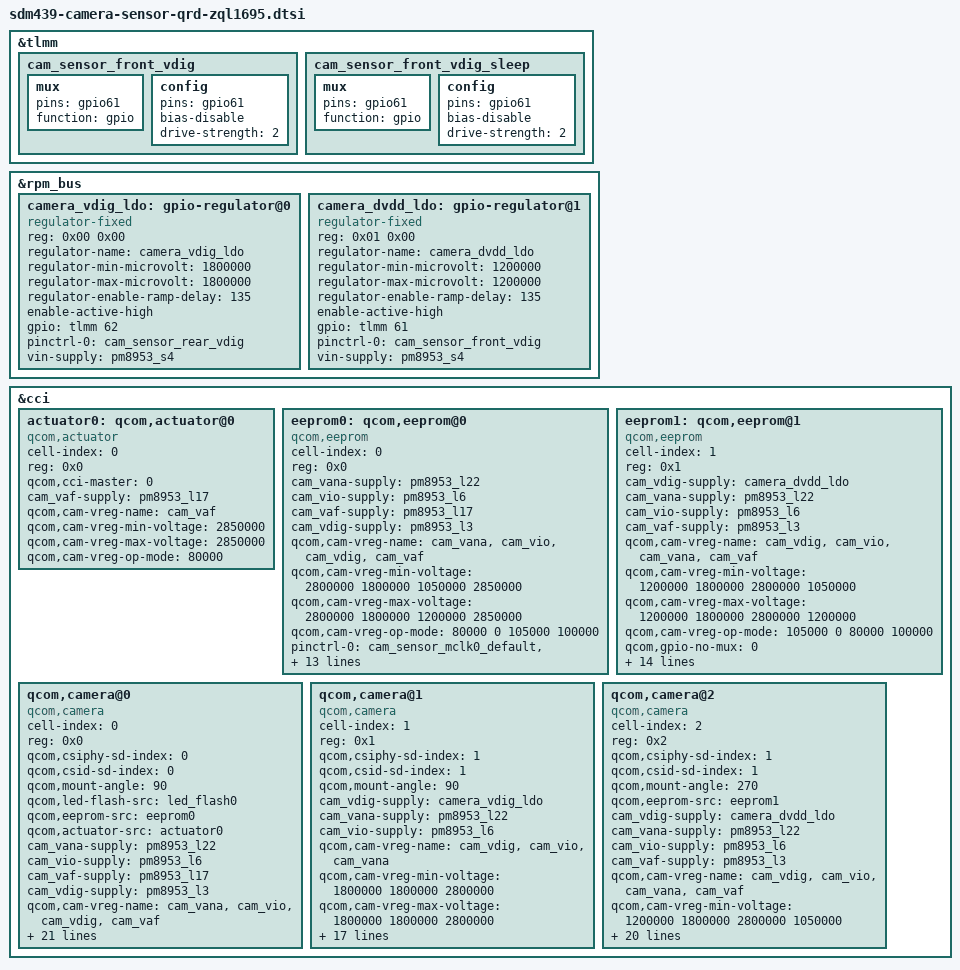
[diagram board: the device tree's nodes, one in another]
/*
 * Copyright (c) 2015-2016, 2018-2019 The Linux Foundation. All rights reserved.
 *
 * This program is free software; you can redistribute it and/or modify
 * it under the terms of the GNU General Public License version 2 and
 * only version 2 as published by the Free Software Foundation.
 *
 * This program is distributed in the hope that it will be useful,
 * but WITHOUT ANY WARRANTY; without even the implied warranty of
 * MERCHANTABILITY or FITNESS FOR A PARTICULAR PURPOSE.  See the
 * GNU General Public License for more details.
 */

#include <dt-bindings/clock/msm-clocks-8952.h>

&tlmm{
		cam_sensor_front_vdig: cam_sensor_front_vdig {
			/* VDIG */
			mux {
				pins = "gpio61";
				function = "gpio";
			};

			config {
				pins = "gpio61";
				bias-disable; /* No PULL */
				drive-strength = <2>; /* 2 MA */
			};
		};

		cam_sensor_front_vdig_sleep: cam_sensor_front_vdig_sleep {
			/* VDIG */
			mux {
				pins = "gpio61";
				function = "gpio";
			};

			config {
				pins = "gpio61";
				bias-disable; /* No PULL */
				drive-strength = <2>; /* 2 MA */
			};
		};
};

&rpm_bus {
	camera_vdig_ldo: gpio-regulator@0 {
		compatible = "regulator-fixed";
		reg = <0x00 0x00>;
		regulator-name = "camera_vdig_ldo";
		regulator-min-microvolt = <1800000>;
		regulator-max-microvolt = <1800000>;
		regulator-enable-ramp-delay = <135>;
		enable-active-high;
		gpio = <&tlmm 62 0>;
		pinctrl-names = "default";
		pinctrl-0 = <&cam_sensor_rear_vdig>;
		vin-supply = <&pm8953_s4>;
	};
	camera_dvdd_ldo: gpio-regulator@1 {
		compatible = "regulator-fixed";
		reg = <0x01 0x00>;
		regulator-name = "camera_dvdd_ldo";
		regulator-min-microvolt = <1200000>;
		regulator-max-microvolt = <1200000>;
		regulator-enable-ramp-delay = <135>;
		enable-active-high;
		gpio = <&tlmm 61 0>;
		pinctrl-names = "default";
		pinctrl-0 = <&cam_sensor_front_vdig>;
		vin-supply = <&pm8953_s4>;
	};
};

&cci {
	#address-cells = <1>;
	#size-cells = <0>;

	actuator0: qcom,actuator@0 {
		cell-index = <0>;
		reg = <0x0>;
		compatible = "qcom,actuator";
		qcom,cci-master = <0>;
		cam_vaf-supply = <&pm8953_l17>;
		qcom,cam-vreg-name = "cam_vaf";
		qcom,cam-vreg-min-voltage = <2850000>;
		qcom,cam-vreg-max-voltage = <2850000>;
		qcom,cam-vreg-op-mode = <80000>;
	};

	eeprom0: qcom,eeprom@0 {
		cell-index = <0>;
		compatible = "qcom,eeprom";
		reg = <0x0>;
		cam_vana-supply = <&pm8953_l22>;
		cam_vio-supply = <&pm8953_l6>;
		cam_vaf-supply = <&pm8953_l17>;
		cam_vdig-supply = <&pm8953_l3>;
		qcom,cam-vreg-name = "cam_vana", "cam_vio",
				"cam_vdig", "cam_vaf";
		qcom,cam-vreg-min-voltage = <2800000 1800000 1050000 2850000>;
		qcom,cam-vreg-max-voltage = <2800000 1800000 1200000 2850000>;
		qcom,cam-vreg-op-mode = <80000 0 105000 100000>;
		pinctrl-names = "cam_default", "cam_suspend";
		pinctrl-0 = <&cam_sensor_mclk0_default
				&cam_sensor_rear_reset>;
		pinctrl-1 = <&cam_sensor_mclk0_sleep
				&cam_sensor_rear_reset_sleep>;
		gpios = <&tlmm 26 0>,
			<&tlmm 36 0>;
		qcom,gpio-reset = <1>;
		qcom,gpio-req-tbl-num = <0 1>;
		qcom,gpio-req-tbl-flags = <1 0>;
		qcom,gpio-req-tbl-label = "CAMIF_MCLK0",
			"CAM_RESET0";
		qcom,cci-master = <0>;
		status = "ok";
		clocks = <&clock_gcc clk_mclk0_clk_src>,
				<&clock_gcc clk_gcc_camss_mclk0_clk>;
		clock-names = "cam_src_clk", "cam_clk";
		qcom,clock-rates = <24000000 0>;
	};

    eeprom1: qcom,eeprom@1 {
		cell-index = <1>;
		compatible = "qcom,eeprom";
		reg = <0x1>;
		cam_vdig-supply = <&camera_dvdd_ldo>;
		cam_vana-supply = <&pm8953_l22>;
		cam_vio-supply = <&pm8953_l6>;
		cam_vaf-supply = <&pm8953_l3>;
		qcom,cam-vreg-name = "cam_vdig", "cam_vio", "cam_vana", "cam_vaf";
		qcom,cam-vreg-min-voltage = <1200000 1800000 2800000 1050000>;
		qcom,cam-vreg-max-voltage = <1200000 1800000 2800000 1200000>;
		qcom,cam-vreg-op-mode = <105000 0 80000 100000>;
		qcom,gpio-no-mux = <0>;
		pinctrl-names = "cam_default", "cam_suspend";
		pinctrl-0 = <&cam_sensor_mclk2_default
				&cam_sensor_front1_default>;
		pinctrl-1 = <&cam_sensor_mclk2_sleep
				&cam_sensor_front1_sleep>;
		gpios = <&tlmm 27 0>,
			<&tlmm 40 0>;
		qcom,gpio-reset = <1>;
		qcom,gpio-req-tbl-num = <0 1>;
		qcom,gpio-req-tbl-flags = <1 0>;
		qcom,gpio-req-tbl-label = "CAMIF_MCLK2",
					  "CAM_RESET2";
		qcom,cci-master = <0>;
		status = "ok";
		clocks = <&clock_gcc clk_mclk2_clk_src>,
			<&clock_gcc clk_gcc_camss_mclk2_clk>;
		clock-names = "cam_src_clk", "cam_clk";
		qcom,clock-rates = <24000000 0>;
	};

	qcom,camera@0 {
		cell-index = <0>;
		compatible = "qcom,camera";
		reg = <0x0>;
		qcom,csiphy-sd-index = <0>;
		qcom,csid-sd-index = <0>;
		qcom,mount-angle = <90>;
		qcom,led-flash-src = <&led_flash0>;
		qcom,eeprom-src = <&eeprom0>;
		qcom,actuator-src = <&actuator0>;
		cam_vana-supply = <&pm8953_l22>;
		cam_vio-supply = <&pm8953_l6>;
		cam_vaf-supply = <&pm8953_l17>;
		cam_vdig-supply = <&pm8953_l3>;
		qcom,cam-vreg-name = "cam_vana", "cam_vio",
				"cam_vdig", "cam_vaf";
		qcom,cam-vreg-min-voltage = <2800000 1800000 1050000 2850000>;
		qcom,cam-vreg-max-voltage = <2800000 1800000 1200000 2850000>;
		qcom,cam-vreg-op-mode = <80000 0 105000 100000>;
		pinctrl-names = "cam_default", "cam_suspend";
		pinctrl-0 = <&cam_sensor_mclk0_default
				&cam_sensor_rear_reset>;
		pinctrl-1 = <&cam_sensor_mclk0_sleep
				&cam_sensor_rear_reset_sleep>;
		gpios = <&tlmm 26 0>,
			<&tlmm 36 0>;
		qcom,gpio-reset = <1>;
		qcom,gpio-req-tbl-num = <0 1>;
		qcom,gpio-req-tbl-flags = <1 0>;
		qcom,gpio-req-tbl-label = "CAMIF_MCLK0",
			"CAM_RESET0";
		qcom,sensor-position = <0>;
		qcom,sensor-mode = <0>;
		qcom,cci-master = <0>;
		status = "ok";
		clocks = <&clock_gcc clk_mclk0_clk_src>,
				<&clock_gcc clk_gcc_camss_mclk0_clk>;
		clock-names = "cam_src_clk", "cam_clk";
		qcom,clock-rates = <24000000 0>;
	};

	qcom,camera@1 {
		cell-index = <1>;
		compatible = "qcom,camera";
		reg = <0x1>;
		qcom,csiphy-sd-index = <1>;
		qcom,csid-sd-index = <1>;
		qcom,mount-angle = <90>;
		cam_vdig-supply = <&camera_vdig_ldo>;
		cam_vana-supply = <&pm8953_l22>;
		cam_vio-supply = <&pm8953_l6>;
		qcom,cam-vreg-name = "cam_vdig", "cam_vio", "cam_vana";
		qcom,cam-vreg-min-voltage = <1800000 1800000 2800000>;
		qcom,cam-vreg-max-voltage = <1800000 1800000 2800000>;
		qcom,cam-vreg-op-mode = <200000 0 80000>;
		pinctrl-names = "cam_default", "cam_suspend";
		pinctrl-0 = <&cam_sensor_mclk1_default
				&cam_sensor_front_default>;
		pinctrl-1 = <&cam_sensor_mclk1_sleep
				&cam_sensor_front_sleep>;
		gpios = <&tlmm 27 0>,
			<&tlmm 38 0>;
		qcom,gpio-reset = <1>;
		qcom,gpio-req-tbl-num = <0 1>;
		qcom,gpio-req-tbl-flags = <1 0>;
		qcom,gpio-req-tbl-label = "CAMIF_MCLK1",
			"CAM_RESET1";
		qcom,sensor-position = <2>;
		qcom,sensor-mode = <1>;
		qcom,cci-master = <1>;
		clocks = <&clock_gcc clk_mclk1_clk_src>,
				<&clock_gcc clk_gcc_camss_mclk1_clk>;
		clock-names = "cam_src_clk", "cam_clk";
		qcom,clock-rates = <24000000 0>;
	};

	qcom,camera@2 {
		cell-index = <2>;
		compatible = "qcom,camera";
		reg = <0x2>;
		qcom,csiphy-sd-index = <1>;
		qcom,csid-sd-index = <1>;
		qcom,mount-angle = <270>;
		qcom,eeprom-src = <&eeprom1>;
		cam_vdig-supply = <&camera_dvdd_ldo>;
		cam_vana-supply = <&pm8953_l22>;
		cam_vio-supply = <&pm8953_l6>;
		cam_vaf-supply = <&pm8953_l3>;
		qcom,cam-vreg-name = "cam_vdig", "cam_vio", "cam_vana","cam_vaf";
		qcom,cam-vreg-min-voltage = <1200000 1800000 2800000 1050000>;
		qcom,cam-vreg-max-voltage = <1200000 1800000 2800000 1200000>;
		qcom,cam-vreg-op-mode = <105000 0 80000 100000>;
		qcom,gpio-no-mux = <0>;
		pinctrl-names = "cam_default", "cam_suspend";
		pinctrl-0 = <&cam_sensor_mclk2_default
				&cam_sensor_front1_default>;
		pinctrl-1 = <&cam_sensor_mclk2_sleep
				&cam_sensor_front1_sleep>;
		gpios = <&tlmm 28 0>,
			<&tlmm 40 0>;
		qcom,gpio-reset = <1>;
		qcom,gpio-req-tbl-num = <0 1>;
		qcom,gpio-req-tbl-flags = <1 0>;
		qcom,gpio-req-tbl-label = "CAMIF_MCLK2",
					  "CAM_RESET2";
		qcom,sensor-position = <1>;
		qcom,sensor-mode = <0>;
		qcom,cci-master = <0>;
		status = "ok";
		clocks = <&clock_gcc clk_mclk2_clk_src>,
			<&clock_gcc clk_gcc_camss_mclk2_clk>;
		clock-names = "cam_src_clk", "cam_clk";
		qcom,clock-rates = <24000000 0>;
	};
};
